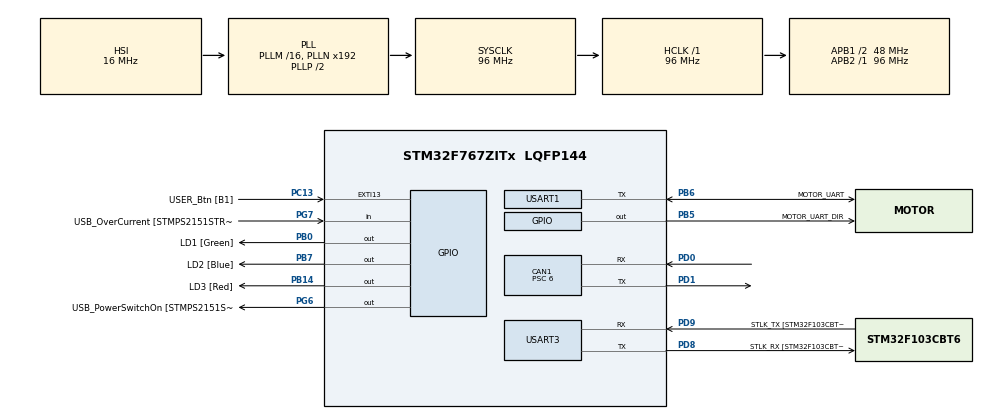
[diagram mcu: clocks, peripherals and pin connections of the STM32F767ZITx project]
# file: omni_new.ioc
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CAN1.BS1=CAN_BS1_13TQ
CAN1.BS2=CAN_BS2_2TQ
CAN1.CalculateBaudRate=500000
CAN1.CalculateTimeBit=2000
CAN1.CalculateTimeQuantum=125.0
CAN1.Prescaler=6
CORTEX_M7.default_mode_Activation=1
FREERTOS.INCLUDE_vTaskDelayUntil=1
FREERTOS.Tasks01=defaultTask,0,256,StartDefaultTask,Default,NULL,Dynamic,NULL,NULL;loggerTaskName,0,1024,loggerTask,As external,NULL,Dynamic,NULL,NULL;servoTaskName,2,2048,servoMotorTask,As external,NULL,Dynamic,NULL,NULL;canRxTaskName,2,512,canRxTask,As external,NULL,Dynamic,NULL,NULL;canTxTaskName,1,512,canTxTask,As external,NULL,Dynamic,NULL,NULL;cliConsoleTaskN,0,512,cliConsoleTask,As external,NULL,Dynamic,NULL,NULL
FREERTOS.configCHECK_FOR_STACK_OVERFLOW=2
FREERTOS.configTOTAL_HEAP_SIZE=24576
FREERTOS.configUSE_COUNTING_SEMAPHORES=1
FREERTOS.configUSE_STATS_FORMATTING_FUNCTIONS=1
FREERTOS.configUSE_TRACE_FACILITY=1
Mcu.Family=STM32F7
Mcu.Name=STM32F767ZITx
Mcu.Package=LQFP144
NVIC.CAN1_RX0_IRQn=true\:5\:0\:false\:false\:true\:true\:true\:true\:true
NVIC.PriorityGroup=NVIC_PRIORITYGROUP_4
PA1.GPIO_Label=RMII_REF_CLK [LAN8742A-CZ-TR_REFCLK0]
PA1.Signal=ETH_REF_CLK
PA10.GPIO_Label=USB_ID
PA10.Signal=USB_OTG_FS_ID
PA11.GPIO_Label=USB_DM
PA11.Signal=USB_OTG_FS_DM
PA12.GPIO_Label=USB_DP
PA12.Signal=USB_OTG_FS_DP
PA13.GPIO_Label=TMS
PA13.Mode=Serial_Wire
PA13.Signal=SYS_JTMS-SWDIO
PA14.GPIO_Label=TCK
PA14.Mode=Serial_Wire
PA14.Signal=SYS_JTCK-SWCLK
PA2.GPIO_Label=RMII_MDIO [LAN8742A-CZ-TR_MDIO]
PA2.Signal=ETH_MDIO
PA7.GPIO_Label=RMII_CRS_DV [LAN8742A-CZ-TR_CRS_DV]
PA7.Signal=ETH_CRS_DV
PA8.GPIO_Label=USB_SOF [TP1]
PA8.Signal=USB_OTG_FS_SOF
PA9.GPIO_Label=USB_VBUS
PA9.Signal=USB_OTG_FS_VBUS
PB0.GPIO_Label=LD1 [Green]
PB0.Signal=GPIO_Output
PB13.GPIO_Label=RMII_TXD1 [LAN8742A-CZ-TR_TXD1]
PB13.Signal=ETH_TXD1
PB14.GPIO_Label=LD3 [Red]
PB14.Signal=GPIO_Output
PB3.GPIO_Label=SW0
PB3.Signal=SYS_JTDO-SWO
PB5.GPIO_Label=MOTOR_UART_DIR
PB5.Signal=GPIO_Output
PB6.GPIO_Label=MOTOR_UART
PB6.GPIO_ModeDefaultOD=GPIO_MODE_AF_PP
PB6.GPIO_PuPd=GPIO_PULLUP
PB6.Mode=Half_duplex(single_wire_mode)
PB6.Signal=USART1_TX
PB7.GPIO_Label=LD2 [Blue]
PB7.Signal=GPIO_Output
PC1.GPIO_Label=RMII_MDC [LAN8742A-CZ-TR_MDC]
PC1.Signal=ETH_MDC
PC13.GPIO_Label=USER_Btn [B1]
PC13.Signal=GPXTI13
PC14/OSC32_IN.Signal=RCC_OSC32_IN
PC15/OSC32_OUT.Signal=RCC_OSC32_OUT
PC4.GPIO_Label=RMII_RXD0 [LAN8742A-CZ-TR_RXD0]
PC4.Signal=ETH_RXD0
PC5.GPIO_Label=RMII_RXD1 [LAN8742A-CZ-TR_RXD1]
PC5.Signal=ETH_RXD1
PD0.Mode=CAN_Activate
PD0.Signal=CAN1_RX
PD1.Mode=CAN_Activate
PD1.Signal=CAN1_TX
PD8.GPIO_Label=STLK_RX [STM32F103CBT6_PA3]
PD8.Mode=Asynchronous
PD8.Signal=USART3_TX
PD9.GPIO_Label=STLK_TX [STM32F103CBT6_PA2]
PD9.Mode=Asynchronous
PD9.Signal=USART3_RX
PG11.GPIO_Label=RMII_TX_EN [LAN8742A-CZ-TR_TXEN]
PG11.Signal=ETH_TX_EN
PG13.GPIO_Label=RMII_TXD0 [LAN8742A-CZ-TR_TXD0]
PG13.Signal=ETH_TXD0
PG6.GPIO_Label=USB_PowerSwitchOn [STMPS2151STR_EN]
PG6.Signal=GPIO_Output
PG7.GPIO_Label=USB_OverCurrent [STMPS2151STR_FAULT]
PG7.Signal=GPIO_Input
PH0/OSC_IN.GPIO_Label=MCO [STM32F103CBT6_PA8]
PH0/OSC_IN.Signal=RCC_OSC_IN
PH1/OSC_OUT.Signal=RCC_OSC_OUT
ProjectManager.HeapSize=0x200
ProjectManager.StackSize=0x400
ProjectManager.TargetToolchain=STM32CubeIDE
RCC.48MHZClocksFreq_Value=24000000
RCC.AHBFreq_Value=96000000
RCC.APB1CLKDivider=RCC_HCLK_DIV2
RCC.APB1Freq_Value=48000000
RCC.APB1TimFreq_Value=96000000
RCC.APB2Freq_Value=96000000
RCC.APB2TimFreq_Value=96000000
RCC.CortexFreq_Value=96000000
RCC.HCLKFreq_Value=96000000
RCC.HSE_VALUE=16000000
RCC.HSI_VALUE=16000000
RCC.LSE_VALUE=32768
RCC.PLLMUL=RCC_PLL_MUL9
RCC.PRESCALERUSB=RCC_USBCLKSOURCE_PLL_DIV1_5
RCC.SYSCLKFreq_VALUE=96000000
RCC.SYSCLKSource=RCC_SYSCLKSOURCE_PLLCLK
RCC.SYSCLKSourceVirtual=RCC_SYSCLKSOURCE_PLLCLK
RCC.USBFreq_Value=96000000
RCC.VCOOutputFreq_Value=192000000
USART1.VirtualMode-Half_duplex(single_wire_mode)=VM_ASYNC
USART3.VirtualMode-Asynchronous=VM_ASYNC
VP_FREERTOS_VS_CMSIS_V1.Mode=CMSIS_V1
board=NUCLEO-F767ZI

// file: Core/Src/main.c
/* USER CODE BEGIN Header */
/**
  ******************************************************************************
  * @file           : main.c
  * @brief          : Main program body
  ******************************************************************************
  * @attention
  *
  * Copyright (c) 2026 STMicroelectronics.
  * All rights reserved.
  *
  * This software is licensed under terms that can be found in the LICENSE file
  * in the root directory of this software component.
  * If no LICENSE file comes with this software, it is provided AS-IS.
  *
  ******************************************************************************
  */
/* USER CODE END Header */
#include "main.h"
#include "cmsis_os.h"
#include "can.h"
#include "usart.h"
#include "gpio.h"

/* USER CODE BEGIN Includes */
#include "bsp.h"
/* USER CODE END Includes */

void SystemClock_Config(void);
static void MPU_Config(void);
void MX_FREERTOS_Init(void);

int main(void)
{

  /* MPU Configuration--------------------------------------------------------*/
  MPU_Config();

  /* MCU Configuration--------------------------------------------------------*/

  /* Reset of all peripherals, Initializes the Flash interface and the Systick. */
  HAL_Init();

  /* Configure the system clock */
  SystemClock_Config();

  /* Initialize all configured peripherals */
  MX_GPIO_Init();
  MX_CAN1_Init();
  MX_USART1_UART_Init();
  MX_USART3_UART_Init();

  /* Call init function for freertos objects (in cmsis_os2.c) */
  MX_FREERTOS_Init();

  /* Start scheduler */
  osKernelStart();

  /* We should never get here as control is now taken by the scheduler */

  /* Infinite loop */
  while (1)
  {

  }
}

void SystemClock_Config(void)
{
  RCC_OscInitTypeDef RCC_OscInitStruct = {0};
  RCC_ClkInitTypeDef RCC_ClkInitStruct = {0};

  /** Configure the main internal regulator output voltage
  */
  __HAL_RCC_PWR_CLK_ENABLE();
  __HAL_PWR_VOLTAGESCALING_CONFIG(PWR_REGULATOR_VOLTAGE_SCALE3);

  /** Initializes the RCC Oscillators according to the specified parameters
  * in the RCC_OscInitTypeDef structure.
  */
  RCC_OscInitStruct.OscillatorType = RCC_OSCILLATORTYPE_HSI;
  RCC_OscInitStruct.HSIState = RCC_HSI_ON;
  RCC_OscInitStruct.HSICalibrationValue = RCC_HSICALIBRATION_DEFAULT;
  RCC_OscInitStruct.PLL.PLLState = RCC_PLL_ON;
  RCC_OscInitStruct.PLL.PLLSource = RCC_PLLSOURCE_HSI;
  RCC_OscInitStruct.PLL.PLLM = 16;
  RCC_OscInitStruct.PLL.PLLN = 192;
  RCC_OscInitStruct.PLL.PLLP = RCC_PLLP_DIV2;
  RCC_OscInitStruct.PLL.PLLQ = 2;
  RCC_OscInitStruct.PLL.PLLR = 2;
  if (HAL_RCC_OscConfig(&RCC_OscInitStruct) != HAL_OK)
  {
    Error_Handler();
  }

  /** Activate the Over-Drive mode
  */
  if (HAL_PWREx_EnableOverDrive() != HAL_OK)
  {
    Error_Handler();
  }

  /** Initializes the CPU, AHB and APB buses clocks
  */
  RCC_ClkInitStruct.ClockType = RCC_CLOCKTYPE_HCLK|RCC_CLOCKTYPE_SYSCLK
                              |RCC_CLOCKTYPE_PCLK1|RCC_CLOCKTYPE_PCLK2;
  RCC_ClkInitStruct.SYSCLKSource = RCC_SYSCLKSOURCE_PLLCLK;
  RCC_ClkInitStruct.AHBCLKDivider = RCC_SYSCLK_DIV1;
  RCC_ClkInitStruct.APB1CLKDivider = RCC_HCLK_DIV2;
  RCC_ClkInitStruct.APB2CLKDivider = RCC_HCLK_DIV1;

  if (HAL_RCC_ClockConfig(&RCC_ClkInitStruct, FLASH_LATENCY_3) != HAL_OK)
  {
    Error_Handler();
  }
}

 /* MPU Configuration */

void MPU_Config(void)
{
  MPU_Region_InitTypeDef MPU_InitStruct = {0};

  /* Disables the MPU */
  HAL_MPU_Disable();

  /** Initializes and configures the Region and the memory to be protected
  */
  MPU_InitStruct.Enable = MPU_REGION_ENABLE;
  MPU_InitStruct.Number = MPU_REGION_NUMBER0;
  MPU_InitStruct.BaseAddress = 0x0;
  MPU_InitStruct.Size = MPU_REGION_SIZE_4GB;
  MPU_InitStruct.SubRegionDisable = 0x87;
  MPU_InitStruct.TypeExtField = MPU_TEX_LEVEL0;
  MPU_InitStruct.AccessPermission = MPU_REGION_NO_ACCESS;
  MPU_InitStruct.DisableExec = MPU_INSTRUCTION_ACCESS_DISABLE;
  MPU_InitStruct.IsShareable = MPU_ACCESS_SHAREABLE;
  MPU_InitStruct.IsCacheable = MPU_ACCESS_NOT_CACHEABLE;
  MPU_InitStruct.IsBufferable = MPU_ACCESS_NOT_BUFFERABLE;

  HAL_MPU_ConfigRegion(&MPU_InitStruct);
  /* Enables the MPU */
  HAL_MPU_Enable(MPU_PRIVILEGED_DEFAULT);

}

void Error_Handler(void)
{
  __disable_irq();
  while (1)
  {
  }
}

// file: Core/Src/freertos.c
/* USER CODE BEGIN Header */
/**
  ******************************************************************************
  * File Name          : freertos.c
  * Description        : Code for freertos applications
  ******************************************************************************
  * @attention
  *
  * Copyright (c) 2026 STMicroelectronics.
  * All rights reserved.
  *
  * This software is licensed under terms that can be found in the LICENSE file
  * in the root directory of this software component.
  * If no LICENSE file comes with this software, it is provided AS-IS.
  *
  ******************************************************************************
  */
/* USER CODE END Header */

#include "FreeRTOS.h"
#include "task.h"
#include "main.h"
#include "cmsis_os.h"

/* USER CODE BEGIN Includes */
#include "logger.h"
#include "app_config.h"
#include "bsp.h"
/* USER CODE END Includes */

osThreadId defaultTaskHandle;
osThreadId loggerTaskNameHandle;
osThreadId servoTaskNameHandle;
osThreadId canRxTaskNameHandle;
osThreadId canTxTaskNameHandle;
osThreadId cliConsoleTaskNHandle;

void StartDefaultTask(void const * argument);
extern void loggerTask(void const * argument);
extern void servoMotorTask(void const * argument);
extern void canRxTask(void const * argument);
extern void canTxTask(void const * argument);
extern void cliConsoleTask(void const * argument);

void MX_FREERTOS_Init(void); /* (MISRA C 2004 rule 8.1) */

/* GetIdleTaskMemory prototype (linked to static allocation support) */
void vApplicationGetIdleTaskMemory( StaticTask_t **ppxIdleTaskTCBBuffer, StackType_t **ppxIdleTaskStackBuffer, uint32_t *pulIdleTaskStackSize );

/* Hook prototypes */
void vApplicationStackOverflowHook(xTaskHandle xTask, signed char *pcTaskName);

/* USER CODE BEGIN 4 */
__weak void vApplicationStackOverflowHook(xTaskHandle xTask, signed char *pcTaskName)
{
   /* Run time stack overflow checking is performed if
   configCHECK_FOR_STACK_OVERFLOW is defined to 1 or 2. This hook function is
   called if a stack overflow is detected. */
}
/* USER CODE END 4 */

/* USER CODE BEGIN GET_IDLE_TASK_MEMORY */
static StaticTask_t xIdleTaskTCBBuffer;
static StackType_t xIdleStack[configMINIMAL_STACK_SIZE];

void vApplicationGetIdleTaskMemory( StaticTask_t **ppxIdleTaskTCBBuffer, StackType_t **ppxIdleTaskStackBuffer, uint32_t *pulIdleTaskStackSize )
{
  *ppxIdleTaskTCBBuffer = &xIdleTaskTCBBuffer;
  *ppxIdleTaskStackBuffer = &xIdleStack[0];
  *pulIdleTaskStackSize = configMINIMAL_STACK_SIZE;
  /* place for user code */
}
/* USER CODE END GET_IDLE_TASK_MEMORY */

void MX_FREERTOS_Init(void) {
  /* USER CODE BEGIN Init */
  logger_init();
  /* USER CODE END Init */

  /* Create the thread(s) */
  /* definition and creation of defaultTask */
  osThreadDef(defaultTask, StartDefaultTask, osPriorityNormal, 0, 256);
  defaultTaskHandle = osThreadCreate(osThread(defaultTask), NULL);

  /* definition and creation of loggerTaskName */
  osThreadDef(loggerTaskName, loggerTask, osPriorityNormal, 0, 1024);
  loggerTaskNameHandle = osThreadCreate(osThread(loggerTaskName), NULL);

  /* definition and creation of servoTaskName */
  osThreadDef(servoTaskName, servoMotorTask, osPriorityHigh, 0, 2048);
  servoTaskNameHandle = osThreadCreate(osThread(servoTaskName), NULL);

  /* definition and creation of canRxTaskName */
  osThreadDef(canRxTaskName, canRxTask, osPriorityHigh, 0, 512);
  canRxTaskNameHandle = osThreadCreate(osThread(canRxTaskName), NULL);

  /* definition and creation of canTxTaskName */
  osThreadDef(canTxTaskName, canTxTask, osPriorityAboveNormal, 0, 512);
  canTxTaskNameHandle = osThreadCreate(osThread(canTxTaskName), NULL);

  /* definition and creation of cliConsoleTaskN */
  osThreadDef(cliConsoleTaskN, cliConsoleTask, osPriorityNormal, 0, 512);
  cliConsoleTaskNHandle = osThreadCreate(osThread(cliConsoleTaskN), NULL);

}

void StartDefaultTask(void const * argument)
{
  /* USER CODE BEGIN StartDefaultTask */

  LOG_INFO("=== OMNI-ROBOT booted ===\r\n");
  LOG_INFO("FW built: %s %s\r\n", __DATE__, __TIME__);
  /* Infinite loop */
  for(;;)
  {
    HAL_GPIO_TogglePin(LED_GPIO_PORT, LED_PIN);
    osDelay(1000);
  }
  /* USER CODE END StartDefaultTask */
}
